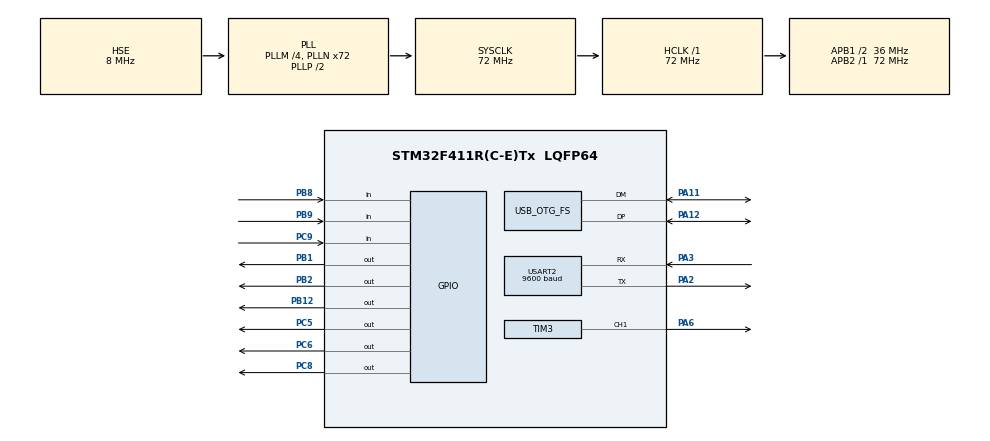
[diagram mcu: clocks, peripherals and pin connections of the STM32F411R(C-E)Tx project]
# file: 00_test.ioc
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Mcu.Family=STM32F4
Mcu.Name=STM32F411R(C-E)Tx
Mcu.Package=LQFP64
NVIC.OTG_FS_IRQn=true\:0\:0\:false\:false\:true\:false\:true\:true
NVIC.PriorityGroup=NVIC_PRIORITYGROUP_4
NVIC.USART2_IRQn=true\:0\:0\:false\:false\:true\:true\:true\:true
PA11.Mode=Device_Only
PA11.Signal=USB_OTG_FS_DM
PA12.Mode=Device_Only
PA12.Signal=USB_OTG_FS_DP
PA13.Mode=Serial_Wire
PA13.Signal=SYS_JTMS-SWDIO
PA14.Mode=Serial_Wire
PA14.Signal=SYS_JTCK-SWCLK
PA2.Mode=Asynchronous
PA2.Signal=USART2_TX
PA3.Mode=Asynchronous
PA3.Signal=USART2_RX
PA6.Signal=S_TIM3_CH1
PB1.Signal=GPIO_Output
PB12.Signal=GPIO_Output
PB2.Signal=GPIO_Output
PB8.Signal=GPIO_Input
PB9.Signal=GPIO_Input
PC5.Signal=GPIO_Output
PC6.Signal=GPIO_Output
PC8.Signal=GPIO_Output
PC9.Signal=GPIO_Input
PH0\ -\ OSC_IN.Mode=HSE-External-Clock-Source
PH0\ -\ OSC_IN.Signal=RCC_OSC_IN
PH1\ -\ OSC_OUT.Mode=HSE-External-Clock-Source
PH1\ -\ OSC_OUT.Signal=RCC_OSC_OUT
ProjectManager.HeapSize=0x200
ProjectManager.StackSize=0x400
ProjectManager.TargetToolchain=STM32CubeIDE
RCC.48MHZClocksFreq_Value=48000000
RCC.AHBFreq_Value=72000000
RCC.APB1CLKDivider=RCC_HCLK_DIV2
RCC.APB1Freq_Value=36000000
RCC.APB1TimFreq_Value=72000000
RCC.APB2Freq_Value=72000000
RCC.APB2TimFreq_Value=72000000
RCC.CortexFreq_Value=72000000
RCC.HCLKFreq_Value=72000000
RCC.HSE_VALUE=8000000
RCC.HSI_VALUE=16000000
RCC.LSE_VALUE=32768
RCC.PLLM=4
RCC.PLLN=72
RCC.PLLQ=3
RCC.RCC_RTC_Clock_Source=RCC_RTCCLKSOURCE_LSI
RCC.SYSCLKFreq_VALUE=72000000
RCC.SYSCLKSource=RCC_SYSCLKSOURCE_PLLCLK
RCC.VCOOutputFreq_Value=144000000
SH.S_TIM3_CH1.0=TIM3_CH1,PWM Generation1 CH1
TIM3.Channel-PWM\ Generation1\ CH1=TIM_CHANNEL_1
TIM3.Period=2000-1
TIM3.Prescaler=1000-1
TIM3.Pulse-PWM\ Generation1\ CH1=300
USART2.BaudRate=9600
USART2.VirtualMode=VM_ASYNC
USB_DEVICE.CLASS_NAME_FS=CDC
USB_DEVICE.VirtualMode=Cdc
USB_DEVICE.VirtualModeFS=Cdc_FS
USB_OTG_FS.VirtualMode=Device_Only
VP_TIM3_VS_ClockSourceINT.Mode=Internal
VP_USB_DEVICE_VS_USB_DEVICE_CDC_FS.Mode=CDC_FS
board=custom

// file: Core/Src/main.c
/* USER CODE BEGIN Header */
/**
  ******************************************************************************
  * @file           : main.c
  * @brief          : Main program body
  ******************************************************************************
  * @attention
  *
  * Copyright (c) 2026 STMicroelectronics.
  * All rights reserved.
  *
  * This software is licensed under terms that can be found in the LICENSE file
  * in the root directory of this software component.
  * If no LICENSE file comes with this software, it is provided AS-IS.
  *
  ******************************************************************************
  */
/* USER CODE END Header */
#include "main.h"
#include "tim.h"
#include "usart.h"
#include "usb_device.h"
#include "gpio.h"

void SystemClock_Config(void);

/* USER CODE BEGIN 0 */

uint8_t uart_rx;
  void HAL_UART_RxCpltCallback(UART_HandleTypeDef *huart)
  {
      if (huart->Instance == USART2) {
          // HM-10 → STM32 → PC
          CDC_Transmit_FS(&uart_rx, 1);
          HAL_UART_Receive_IT(&huart2, &uart_rx, 1);
      }
  }

/* USER CODE END 0 */

int main(void)
{

  /* MCU Configuration--------------------------------------------------------*/

  /* Reset of all peripherals, Initializes the Flash interface and the Systick. */
  HAL_Init();

  /* Configure the system clock */
  SystemClock_Config();

  /* Initialize all configured peripherals */
  MX_GPIO_Init();
  MX_USART2_UART_Init();
  MX_TIM3_Init();
  MX_USB_DEVICE_Init();
  /* USER CODE BEGIN 2 */

  HAL_UART_Receive_IT(&huart2, &uart_rx, 1);

  /* USER CODE END 2 */

  /* Infinite loop */
  while (1)
  {

  }
}

void SystemClock_Config(void)
{
  RCC_OscInitTypeDef RCC_OscInitStruct = {0};
  RCC_ClkInitTypeDef RCC_ClkInitStruct = {0};

  /** Configure the main internal regulator output voltage
  */
  __HAL_RCC_PWR_CLK_ENABLE();
  __HAL_PWR_VOLTAGESCALING_CONFIG(PWR_REGULATOR_VOLTAGE_SCALE1);

  /** Initializes the RCC Oscillators according to the specified parameters
  * in the RCC_OscInitTypeDef structure.
  */
  RCC_OscInitStruct.OscillatorType = RCC_OSCILLATORTYPE_HSE;
  RCC_OscInitStruct.HSEState = RCC_HSE_BYPASS;
  RCC_OscInitStruct.PLL.PLLState = RCC_PLL_ON;
  RCC_OscInitStruct.PLL.PLLSource = RCC_PLLSOURCE_HSE;
  RCC_OscInitStruct.PLL.PLLM = 4;
  RCC_OscInitStruct.PLL.PLLN = 72;
  RCC_OscInitStruct.PLL.PLLP = RCC_PLLP_DIV2;
  RCC_OscInitStruct.PLL.PLLQ = 3;
  if (HAL_RCC_OscConfig(&RCC_OscInitStruct) != HAL_OK)
  {
    Error_Handler();
  }

  /** Initializes the CPU, AHB and APB buses clocks
  */
  RCC_ClkInitStruct.ClockType = RCC_CLOCKTYPE_HCLK|RCC_CLOCKTYPE_SYSCLK
                              |RCC_CLOCKTYPE_PCLK1|RCC_CLOCKTYPE_PCLK2;
  RCC_ClkInitStruct.SYSCLKSource = RCC_SYSCLKSOURCE_PLLCLK;
  RCC_ClkInitStruct.AHBCLKDivider = RCC_SYSCLK_DIV1;
  RCC_ClkInitStruct.APB1CLKDivider = RCC_HCLK_DIV2;
  RCC_ClkInitStruct.APB2CLKDivider = RCC_HCLK_DIV1;

  if (HAL_RCC_ClockConfig(&RCC_ClkInitStruct, FLASH_LATENCY_2) != HAL_OK)
  {
    Error_Handler();
  }
}

void Error_Handler(void)
{
  __disable_irq();
  while (1)
  {
  }
}
